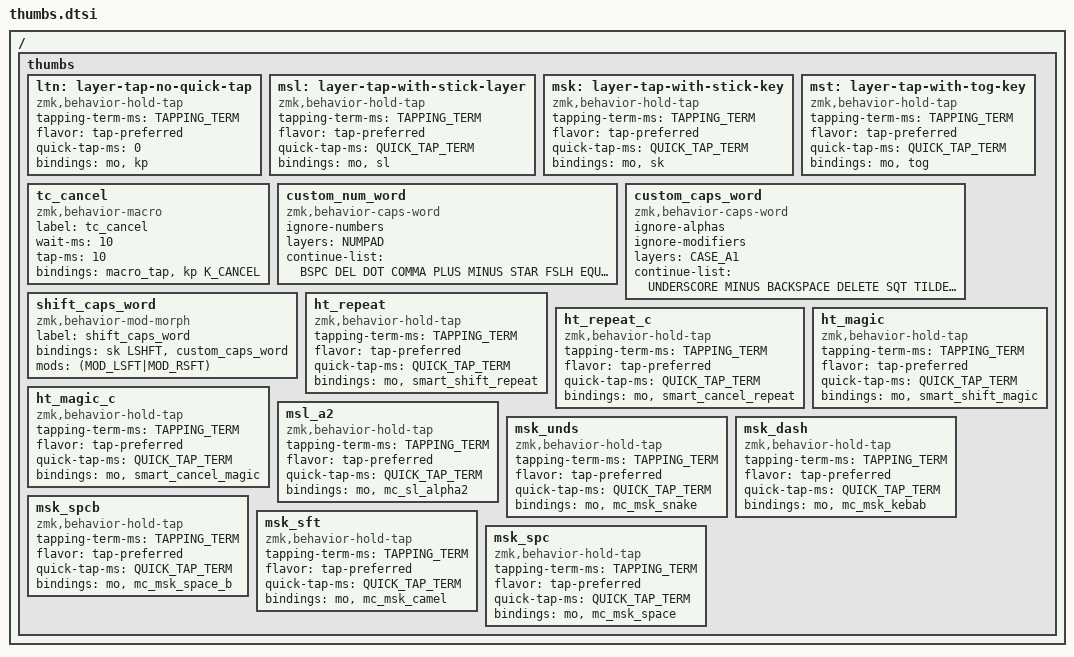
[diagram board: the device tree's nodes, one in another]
/*
*
* Copyright (c) 2022 Rafael Romão
* SPDX-License-Identifier: MIT
*
*/

/ {
    #define THUMB_LAYERTAP(NAME, BINDINGS) \
         NAME: NAME { \
            compatible = "zmk,behavior-hold-tap"; \
            #binding-cells = <2>; \
            tapping-term-ms = <TAPPING_TERM>; \
            flavor = "tap-preferred"; \
            quick-tap-ms = <QUICK_TAP_TERM>; \
            require-prior-idle-ms = <QUICK_TAP_TERM>; \
            bindings = <&mo>, <BINDINGS>; \
        };

    #define THUMB_MACRO(NAME, BINDINGS) \
        NAME: NAME { \
			compatible = "zmk,behavior-macro"; \
            #binding-cells = <0>; \
            wait-ms = <10>; \
            tap-ms = <10>; \
            bindings = <&macro_tap BINDINGS>; \
        };

    #define THUMB_MORPH(NAME, MODS, MODDED, UNMODDED) \
        NAME: NAME { \
            compatible = "zmk,behavior-mod-morph"; \
            #binding-cells = <0>; \
            bindings = <UNMODDED>, <MODDED>; \
            mods = <(MODS)>; \
        };

    #define THUMB_COMBO_MORPH(NAME, FIRST_MOD, SECOND_MOD, IF_BOTH, OR_ELSE) \
        NAME##_CHECK_SECOND: NAME##_CHECK_SECOND { \
            compatible = "zmk,behavior-mod-morph"; \
            #binding-cells = <0>; \
            bindings = <OR_ELSE>, <IF_BOTH>; \
            mods = <(SECOND_MOD)>; \
        }; \
        NAME: NAME { \
            compatible = "zmk,behavior-mod-morph"; \
            #binding-cells = <0>; \
            bindings = <OR_ELSE>, <&NAME##_CHECK_SECOND>; \
            mods = <(FIRST_MOD)>; \
        };

    #define SMART_REPEAT(NAME, LABEL, DEFAULT) \
        NAME: NAME { \
            compatible = "zmk,behavior-antecedent-morph"; \
            label = LABEL; \
            #binding-cells = <0>; \
            max-delay-ms = <ADAPTIVE_KEY_TIMEOUT>; \
            defaults = <DEFAULT>; \
            antecedents = < \
                           A             AACU_TERM     ATIL_TERM     ACIR_TERM     AGRV_TERM        B              C             C_CEDIL          D           \
                           E             EACU_TERM     ECIR_TERM     F             G                H              I             IACU_TERM        J           \
                           K             L             M             N             O                OACU_TERM      OTIL_TERM     OCIR_TERM        P           \
                           Q             QU_TERM       R             S             T                U              UACU_TERM     V                W           \
                           X             Y             Z             DOT           \
                           LS(A)         C_AACU_TERM   C_ATIL_TERM   C_ACIR_TERM   C_AGRV_TERM      LS(B)          LS(C)         LS(C_CEDIL)      LS(D)       \
                           LS(E)         C_EACU_TERM   C_ECIR_TERM   LS(F)         LS(G)            LS(H)          LS(I)         C_IACU_TERM      LS(J)       \
                           LS(K)         LS(L)         LS(M)         LS(N)         LS(O)            C_OACU_TERM    C_OTIL_TERM   C_OCIR_TERM      LS(P)       \
                           LS(Q)         C_QU_TERM     LS(R)         LS(S)         LS(T)            LS(U)          C_UACU_TERM   LS(V)            LS(W)       \
                           LS(X)         LS(Y)         LS(Z)         \
                           >; \
            bindings =    < \
                           &tc_nd        &kp V         &kp O         &kp N         &mc_qu           &key_repeat    &key_repeat   &tc_otiles       &key_repeat \
                           &key_repeat   &kp V         &kp E         &key_repeat   &key_repeat      &tc_oes        &tc_ng        &kp V            &ac_aacu    \
                           &tc_ey        &key_repeat   &key_repeat   &key_repeat   &key_repeat      &kp V          &tc_es        &kp O            &key_repeat \
                           &key_repeat   &ac_ecir      &key_repeat   &key_repeat   &key_repeat      &kp Y          &kp V         &ac_aacu         &tc_hy      \
                           &ac_aacu      &tc_ou        &key_repeat   &tc_com       \
                           &tc_nd_c      &kp LS(V)     &kp LS(O)     &kp LS(N)     &mc_qu_c         &key_repeat    &key_repeat   &tc_otiles_c     &key_repeat \
                           &key_repeat   &kp LS(V)     &kp LS(E)     &key_repeat   &key_repeat      &tc_oes_c      &tc_ng_c      &kp LS(V)        &ac_aacu_c    \
                           &tc_ey_c      &key_repeat   &key_repeat   &key_repeat   &key_repeat      &kp LS(V)      &tc_es_c      &kp LS(O)        &key_repeat \
                           &key_repeat   &ac_ecir_c    &key_repeat   &key_repeat   &key_repeat      &kp LS(Y)      &kp LS(V)     &ac_aacu_c       &tc_hy_c      \
                           &ac_aacu_c    &tc_ou_c      &key_repeat   \
                           >; \
        };

    #define SMART_MAGIC(NAME, LABEL, DEFAULT) \
        NAME: NAME { \
            compatible = "zmk,behavior-antecedent-morph"; \
            label = LABEL; \
            #binding-cells = <0>; \
            max-delay-ms = <ADAPTIVE_KEY_TIMEOUT>; \
            defaults = <DEFAULT>; \
            antecedents = < \
                           A             AACU_TERM     ATIL_TERM     ACIR_TERM     AGRV_TERM       B                             C_CEDIL         D         \
                           E             EACU_TERM     ECIR_TERM     F                                           I               IACU_TERM                 \
                           K             L             M             N                             OACU_TERM     OTIL_TERM       OCIR_TERM       P         \
                           Q             QU_TERM       R                           T               U             UACU_TERM       V               W         \
                           X             DOT           \
                           LS(A)         C_AACU_TERM   C_ATIL_TERM   C_ACIR_TERM   C_AGRV_TERM     LS(B)                         LS(C_CEDIL)     LS(D)     \
                           LS(E)         C_EACU_TERM   C_ECIR_TERM   LS(F)                                       LS(I)           C_IACU_TERM               \
                           LS(K)         LS(L)         LS(M)         LS(N)                         C_OACU_TERM   C_OTIL_TERM     C_OCIR_TERM     LS(P)     \
                           LS(Q)         C_QU_TERM     LS(R)                       LS(T)           LS(U)         C_UACU_TERM     LS(V)           LS(W)     \
                           LS(X)         \
                           >; \
            bindings =    < \
                           &kp O         &kp X         &kp O         &kp M         &mc_qu          &kp Y                         &tc_atilo       &kp Y     \
                           &kp U         &kp U         &kp X         &kp Y                                       &tc_smart_i     &kp Z                     \
                           &kp W         &kp H         &kp S         &kp F                         &kp X         &kp E           &kp V           &kp T     \
                           &key_repeat   &ac_iacu      &kp L                       &kp W           &kp E         &kp Z           &ac_iacu        &kp K     \
                           &ac_iacu      &kp SLASH     \
                           &kp LS(O)     &kp LS(X)     &kp LS(O)     &kp LS(M)     &mc_qu_c        &kp LS(Y)                     &tc_atilo_c     &kp LS(Y) \
                           &kp LS(U)     &kp LS(U)     &kp LS(X)     &kp LS(Y)                                   &tc_smart_i     &kp LS(Z)                 \
                           &kp LS(W)     &kp LS(H)     &kp LS(S)     &kp LS(F)                     &kp LS(X)     &kp LS(E)       &kp LS(V)       &kp LS(T) \
                           &key_repeat   &ac_iacu_c    &kp LS(L)                   &kp LS(W)       &kp LS(E)     &kp LS(Z)       &ac_iacu_c      &kp LS(K) \
                           &ac_iacu_c    \
                           >; \
        };

    thumbs {
        
        // ********************** CUSTOM HOLD TAPS ********************** //

        ltn: layer-tap-no-quick-tap {
            compatible = "zmk,behavior-hold-tap";
            #binding-cells = <2>;
            tapping-term-ms = <TAPPING_TERM>;
            flavor = "tap-preferred";
            quick-tap-ms = <0>;
            bindings = <&mo>, <&kp>;
        };
        msl: layer-tap-with-stick-layer {
            compatible = "zmk,behavior-hold-tap";
            #binding-cells = <2>;
            tapping-term-ms = <TAPPING_TERM>;
            flavor = "tap-preferred";
            quick-tap-ms = <QUICK_TAP_TERM>;
            bindings = <&mo>, <&sl>;
        };
        msk: layer-tap-with-stick-key {
            compatible = "zmk,behavior-hold-tap";
            #binding-cells = <2>;
            tapping-term-ms = <TAPPING_TERM>;
            flavor = "tap-preferred";
            quick-tap-ms = <QUICK_TAP_TERM>;
            bindings = <&mo>, <&sk>;
        };
        mst: layer-tap-with-tog-key {
            compatible = "zmk,behavior-hold-tap";
            #binding-cells = <2>;
            tapping-term-ms = <TAPPING_TERM>;
            flavor = "tap-preferred";
            quick-tap-ms = <QUICK_TAP_TERM>;
            bindings = <&mo>, <&tog>;
        };

        // ********************** SENTENCE CASE ********************** //

        tc_cancel: tc_cancel {
			compatible = "zmk,behavior-macro";
            label = "tc_cancel";
            #binding-cells = <0>;
            wait-ms = <10>;
            tap-ms = <10>;
            bindings = <&macro_tap &kp K_CANCEL>;
        };
        THUMB_MACRO(tc_sp_ns,         &kp SPACE &sl SEN_E1)
        THUMB_MACRO(tc_nsen,          &sl SEN_E1)
        THUMB_LAYERTAP(th_sp_ns,      &tc_sp_ns)
        THUMB_LAYERTAP(th_cancel,     &tc_cancel)
        THUMB_LAYERTAP(th_nsen,       &tc_nsen)

        // ********************** NUM WORD ********************** //

        custom_num_word: custom_num_word {
            compatible = "zmk,behavior-caps-word";
            ignore-numbers;
			#binding-cells = <0>;
            layers = <NUMPAD>;
            continue-list = <BSPC DEL DOT COMMA PLUS MINUS STAR FSLH EQUAL MOVE_LEFT MOVE_RIGHT MOVE_UP MOVE_DOWN SCRL_DOWN SCRL_UP RCLK LCLK>;
        };

        THUMB_MACRO(tc_custom_num_word,     &to ALPHA1 &custom_num_word)

        // ******************* SMART SHIFT / CAPS WORD ******************* //

        custom_caps_word: custom_caps_word {
            compatible = "zmk,behavior-caps-word";
            ignore-alphas;
            ignore-modifiers;
			#binding-cells = <0>;  
            layers = <CASE_A1>;
            continue-list = <UNDERSCORE MINUS BACKSPACE DELETE SQT TILDE CARET GRAVE >;
        };

        shift_caps_word: shift_caps_word {
            compatible = "zmk,behavior-mod-morph";
            label = "shift_caps_word";
            #binding-cells = <0>;
            bindings = <&sk LSHFT>, <&custom_caps_word>;
            mods = <(MOD_LSFT|MOD_RSFT)>;
        };

        // ******************** SMART SHIFT / REPEAT KEY ******************** //

        SMART_REPEAT(smart_shift_repeat, "smart_shift_repeat", &shift_caps_word)
        SMART_REPEAT(smart_cancel_repeat, "smart_cancel_repeat", &tc_cancel)

        THUMB_MACRO(tc_nd,        &kp N &kp D)
        THUMB_MACRO(tc_oes,       &ac_otil &kp E &kp S)
        THUMB_MACRO(tc_es,        &kp E &kp S)
        THUMB_MACRO(tc_ou,        &kp O &kp U)
        THUMB_MACRO(tc_ng,        &kp N &kp G)
        THUMB_MACRO(tc_ey,        &kp E &kp Y)
        THUMB_MACRO(tc_hy,        &kp H &kp Y)
        THUMB_MACRO(tc_otiles,    &ac_otil &kp E &kp S)
        THUMB_MACRO(tc_com,       &kp C &kp O &kp M)
        THUMB_MACRO(tc_nd_c,      &kp LS(N) &kp LS(D))
        THUMB_MACRO(tc_oes_c,     &ac_otil_c &kp LS(E) &kp LS(S))
        THUMB_MACRO(tc_es_c,      &kp LS(E) &kp LS(S))
        THUMB_MACRO(tc_ou_c,      &kp LS(O) &kp LS(U))
        THUMB_MACRO(tc_ng_c,      &kp LS(N) &kp LS(G))
        THUMB_MACRO(tc_ey_c,      &kp LS(E) &kp LS(Y))
        THUMB_MACRO(tc_hy_c,      &kp LS(H) &kp LS(Y))
        THUMB_MACRO(tc_otiles_c,  &ac_otil_c &kp LS(E) &kp LS(S))

        ht_repeat: ht_repeat {
            compatible = "zmk,behavior-hold-tap";
            #binding-cells = <2>;
            tapping-term-ms = <TAPPING_TERM>;
            flavor = "tap-preferred";
            quick-tap-ms = <QUICK_TAP_TERM>;
            bindings = <&mo>, <&smart_shift_repeat>;
        };

        ht_repeat_c: ht_repeat_c {
            compatible = "zmk,behavior-hold-tap";
            #binding-cells = <2>;
            tapping-term-ms = <TAPPING_TERM>;
            flavor = "tap-preferred";
            quick-tap-ms = <QUICK_TAP_TERM>;
            bindings = <&mo>, <&smart_cancel_repeat>;
        };

        // ******************** SMART SHIFT / MAGIC KEY ******************** //

        SMART_MAGIC(smart_shift_magic, "smart_shift_magic", &shift_caps_word)
        SMART_MAGIC(smart_cancel_magic, "smart_cancel_magic", &tc_cancel)

        THUMB_MACRO(tc_atilo,   &ac_atil &kp O)
        THUMB_MACRO(tc_atilo_c, &ac_atil_c &kp LS(O))
        THUMB_MACRO(tc_smart_i, &kp BACKSPACE &kp LS(I) &kp QUOT &kp SPACE)

        ht_magic: ht_magic {
            compatible = "zmk,behavior-hold-tap";
            #binding-cells = <2>;
            tapping-term-ms = <TAPPING_TERM>;
            flavor = "tap-preferred";
            quick-tap-ms = <QUICK_TAP_TERM>;
            bindings = <&mo>, <&smart_shift_magic>;
        };

        ht_magic_c: ht_magic_c {
            compatible = "zmk,behavior-hold-tap";
            #binding-cells = <2>;
            tapping-term-ms = <TAPPING_TERM>;
            flavor = "tap-preferred";
            quick-tap-ms = <QUICK_TAP_TERM>;
            bindings = <&mo>, <&smart_cancel_magic>;
        };

        // ******************** SMART CASES ******************** //

        THUMB_MACRO(mc_sl_alpha2,  &sl ALPHA2)

        msl_a2: msl_a2 {
            compatible = "zmk,behavior-hold-tap";
            #binding-cells = <2>;
            tapping-term-ms = <TAPPING_TERM>;
            flavor = "tap-preferred";
            quick-tap-ms = <QUICK_TAP_TERM>;
            bindings = <&mo>, <&mc_sl_alpha2>;
        };

        THUMB_MORPH(sc_caps_word,  MOD_LCTL, &custom_caps_word         , &msl_a2 RAISE 0 )
        THUMB_MORPH(sc_caps_lock,  MOD_RCTL, &to CASE_A1               , &sc_caps_word   )
        THUMB_MORPH(sc_numpad,     MOD_LALT, &to NUMPAD                , &sc_caps_lock   )
        THUMB_MORPH(sc_numword,    MOD_RALT, &custom_num_word          , &sc_numpad      )
        THUMB_MORPH(sc_camelcase,  MOD_RSFT, &to CAMEL_CASE            , &sc_numword     )
        THUMB_MORPH(sc_snakecase,  MOD_LGUI, &to SNAKE_CASE            , &sc_camelcase   )
        THUMB_MORPH(sc_kebabcase,  MOD_RGUI, &to KEBAB_CASE            , &sc_snakecase   )

        THUMB_MACRO(tc_shift_camel,  &to CAMEL_CASE &sl SMART_CASE_S)
        THUMB_COMBO_MORPH(sc_pascalcase, MOD_LCTL, MOD_RSFT|MOD_LSFT, &tc_shift_camel, &sc_kebabcase)

        THUMB_MACRO(tc_strong_snakecase,  &tog SMART_CASE_S &tog SNAKE_CASE)
        THUMB_COMBO_MORPH(sc_strong_snake_case, MOD_LCTL, MOD_LGUI, &tc_strong_snakecase, &sc_pascalcase)
        
        THUMB_MACRO(tc_strong_kebabcase,  &tog SMART_CASE_S &tog KEBAB_CASE)
        THUMB_COMBO_MORPH(sc_strong_kebab_case, MOD_RCTL, MOD_RGUI, &tc_strong_kebabcase, &sc_strong_snake_case)
        
        #define msl_raise_smart sc_strong_kebab_case

        THUMB_MACRO(mc_msk_camel, &sl SMART_CASE_S)
        THUMB_MACRO(mc_msk_snake, &kp UNDERSCORE &sl SPACING)
        THUMB_MACRO(mc_msk_kebab, &kp MINUS &sl SPACING)
        THUMB_MACRO(mc_msk_space, &kp SPACE &to ALPHA1)
        THUMB_MACRO(mc_msk_space_b, &kp BACKSPACE &kp SPACE &to ALPHA1)

        msk_unds: msk_unds {
            compatible = "zmk,behavior-hold-tap";
            #binding-cells = <2>;
            tapping-term-ms = <TAPPING_TERM>;
            flavor = "tap-preferred";
            quick-tap-ms = <QUICK_TAP_TERM>;
            bindings = <&mo>, <&mc_msk_snake>;
        };

        msk_dash: msk_dash {
            compatible = "zmk,behavior-hold-tap";
            #binding-cells = <2>;
            tapping-term-ms = <TAPPING_TERM>;
            flavor = "tap-preferred";
            quick-tap-ms = <QUICK_TAP_TERM>;
            bindings = <&mo>, <&mc_msk_kebab>;
        };

        msk_spcb: msk_spcb {
            compatible = "zmk,behavior-hold-tap";
            #binding-cells = <2>;
            tapping-term-ms = <TAPPING_TERM>;
            flavor = "tap-preferred";
            quick-tap-ms = <QUICK_TAP_TERM>;
            bindings = <&mo>, <&mc_msk_space_b>;
        };

        msk_sft: msk_sft {
            compatible = "zmk,behavior-hold-tap";
            #binding-cells = <2>;
            tapping-term-ms = <TAPPING_TERM>;
            flavor = "tap-preferred";
            quick-tap-ms = <QUICK_TAP_TERM>;
            bindings = <&mo>, <&mc_msk_camel>;
        };

        msk_spc: msk_spc {
            compatible = "zmk,behavior-hold-tap";
            #binding-cells = <2>;
            tapping-term-ms = <TAPPING_TERM>;
            flavor = "tap-preferred";
            quick-tap-ms = <QUICK_TAP_TERM>;
            bindings = <&mo>, <&mc_msk_space>;
        };

    };
};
